VERSION ""

NS_ :

BS_:

BU_: BMS Third_Party_Device

BO_ 1712 MSGID_0X6B0: 8 BMS
 SG_ Pack_Current : 7|16@0- (0.1,0) [32769|32767] "Amps"  Third_Party_Device
 SG_ Pack_Summed_Voltage : 23|16@0+ (0.1,0) [0|65535] "Volts"  Third_Party_Device
 SG_ Pack_SOC : 39|8@0+ (0.5,0) [0|255] "Percent"  Third_Party_Device
 SG_ MultiPurpose_Input_2 : 40|1@1+ (1.0,0) [0|1] ""  Third_Party_Device
 SG_ MultiPurpose_Input_3 : 41|1@1+ (1.0,0) [0|1] ""  Third_Party_Device
 SG_ Blank : 42|1@1+ (1.0,0) [0|1] ""  Third_Party_Device
 SG_ MultiPurpose_Output_2 : 43|1@1+ (1.0,0) [0|1] ""  Third_Party_Device
 SG_ MultiPurpose_Output_3 : 44|1@1+ (1.0,0) [0|1] ""  Third_Party_Device
 SG_ MultiPurpose_Output_4 : 45|1@1+ (1.0,0) [0|1] ""  Third_Party_Device
 SG_ MultiPurpose_Enable : 46|1@1+ (1.0,0) [0|1] ""  Third_Party_Device
 SG_ MultiPurpose_Output : 47|1@1+ (1.0,0) [0|1] ""  Third_Party_Device
 SG_ Discharge_Relay : 48|1@1+ (1.0,0) [0|1] ""  Third_Party_Device
 SG_ Charge_Relay : 49|1@1+ (1.0,0) [0|1] ""  Third_Party_Device
 SG_ Charger_Safety : 50|1@1+ (1.0,0) [0|1] ""  Third_Party_Device
 SG_ Error_MIL_Output : 51|1@1+ (1.0,0) [0|1] ""  Third_Party_Device
 SG_ MultiPurpose_Input : 52|1@1+ (1.0,0) [0|1] ""  Third_Party_Device
 SG_ Constant_1 : 53|1@1+ (1.0,0) [0|1] ""  Third_Party_Device
 SG_ Ready_Power_Signal : 54|1@1+ (1.0,0) [0|1] ""  Third_Party_Device
 SG_ Charge_Power_Signal : 55|1@1+ (1.0,0) [0|1] ""  Third_Party_Device
 SG_ CRC_Checksum : 63|8@0+ (1.0,1) [0|0] ""  Third_Party_Device

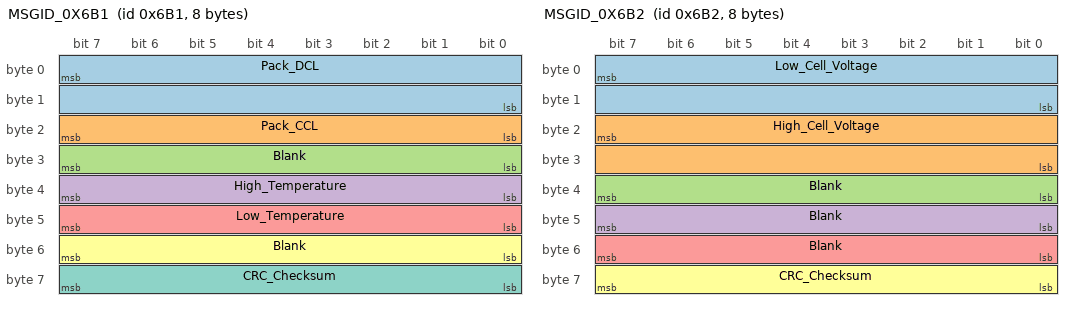
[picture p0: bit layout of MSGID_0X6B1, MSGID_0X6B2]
BO_ 1713 MSGID_0X6B1: 8 BMS
 SG_ Pack_DCL : 7|16@0+ (1.0,0) [0|65535] "Amps"  Third_Party_Device
 SG_ Pack_CCL : 23|8@0+ (1.0,0) [0|255] "Amps"  Third_Party_Device
 SG_ Blank : 31|8@0+ (1.0,0) [0|0] ""  Third_Party_Device
 SG_ High_Temperature : 39|8@0- (1.0,0) [65408|127] "Celsius"  Third_Party_Device
 SG_ Low_Temperature : 47|8@0- (1.0,0) [65408|127] "Celsius"  Third_Party_Device
 SG_ Blank : 55|8@0+ (1.0,0) [0|0] ""  Third_Party_Device
 SG_ CRC_Checksum : 63|8@0+ (1.0,1721) [0|0] ""  Third_Party_Device

BO_ 1714 MSGID_0X6B2: 8 BMS
 SG_ Low_Cell_Voltage : 7|16@0+ (1.0E-4,0) [0|65535] "Volts"  Third_Party_Device
 SG_ High_Cell_Voltage : 23|16@0+ (1.0E-4,0) [0|65535] "Volts"  Third_Party_Device
 SG_ Blank : 39|8@0+ (1.0,0) [0|0] ""  Third_Party_Device
 SG_ Blank : 47|8@0+ (1.0,0) [0|0] ""  Third_Party_Device
 SG_ Blank : 55|8@0+ (1.0,0) [0|0] ""  Third_Party_Device
 SG_ CRC_Checksum : 63|8@0+ (1.0,0) [0|0] ""  Third_Party_Device

BO_ 1281 MSGID_0X501: 2 Third_Party_Device
 SG_ MPO4_State : 7|8@0+ (1.0,0) [0|0] "ON/OFF"  BMS
 SG_ MPO3_State : 15|8@0+ (1.0,0) [0|0] "ON/OFF"  BMS

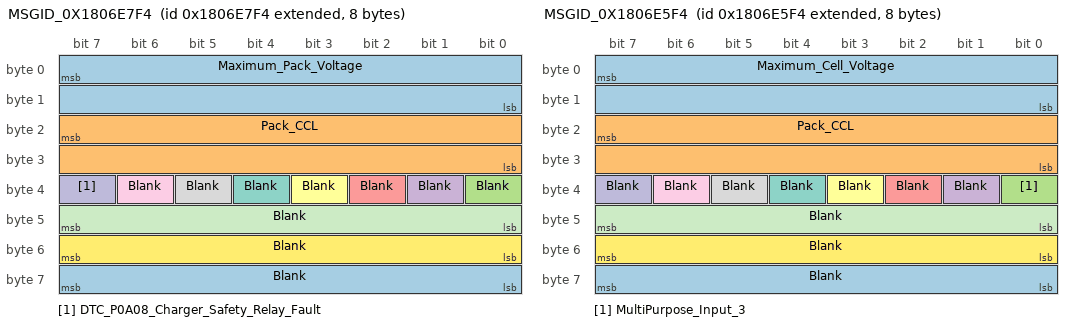
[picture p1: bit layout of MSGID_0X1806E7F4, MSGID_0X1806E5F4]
BO_ 2550589428 MSGID_0X1806E7F4: 8 BMS
 SG_ Maximum_Pack_Voltage : 7|16@0+ (0.1,0) [0|0] "Volts"  Third_Party_Device
 SG_ Pack_CCL : 23|16@0+ (0.1,0) [0|0] "Amps"  Third_Party_Device
 SG_ Blank : 32|1@1+ (1.0,0) [0|1] ""  Third_Party_Device
 SG_ Blank : 33|1@1+ (1.0,0) [0|1] ""  Third_Party_Device
 SG_ Blank : 34|1@1+ (1.0,0) [0|1] ""  Third_Party_Device
 SG_ Blank : 35|1@1+ (1.0,0) [0|1] ""  Third_Party_Device
 SG_ Blank : 36|1@1+ (1.0,0) [0|1] ""  Third_Party_Device
 SG_ Blank : 37|1@1+ (1.0,0) [0|1] ""  Third_Party_Device
 SG_ Blank : 38|1@1+ (1.0,0) [0|1] ""  Third_Party_Device
 SG_ DTC_P0A08_Charger_Safety_Relay_Fault : 39|1@1+ (1.0,0) [0|1] ""  Third_Party_Device
 SG_ Blank : 47|8@0+ (0.1,0) [0|0] ""  Third_Party_Device
 SG_ Blank : 55|8@0+ (1.0,0) [0|0] ""  Third_Party_Device
 SG_ Blank : 63|8@0+ (1.0,0) [0|0] ""  Third_Party_Device

BO_ 2550588916 MSGID_0X1806E5F4: 8 BMS
 SG_ Maximum_Cell_Voltage : 7|16@0+ (0.001,0) [0|0] "Volts"  Third_Party_Device
 SG_ Pack_CCL : 23|16@0+ (0.1,0) [0|0] "Amps"  Third_Party_Device
 SG_ MultiPurpose_Input_3 : 32|1@1+ (1.0,0) [0|1] ""  Third_Party_Device
 SG_ Blank : 33|1@1+ (1.0,0) [0|1] ""  Third_Party_Device
 SG_ Blank : 34|1@1+ (1.0,0) [0|1] ""  Third_Party_Device
 SG_ Blank : 35|1@1+ (1.0,0) [0|1] ""  Third_Party_Device
 SG_ Blank : 36|1@1+ (1.0,0) [0|1] ""  Third_Party_Device
 SG_ Blank : 37|1@1+ (1.0,0) [0|1] ""  Third_Party_Device
 SG_ Blank : 38|1@1+ (1.0,0) [0|1] ""  Third_Party_Device
 SG_ Blank : 39|1@1+ (1.0,0) [0|1] ""  Third_Party_Device
 SG_ Blank : 47|8@0+ (1.0,4) [0|0] ""  Third_Party_Device
 SG_ Blank : 55|8@0+ (1.0,0) [0|0] ""  Third_Party_Device
 SG_ Blank : 63|8@0+ (1.0,0) [0|0] ""  Third_Party_Device

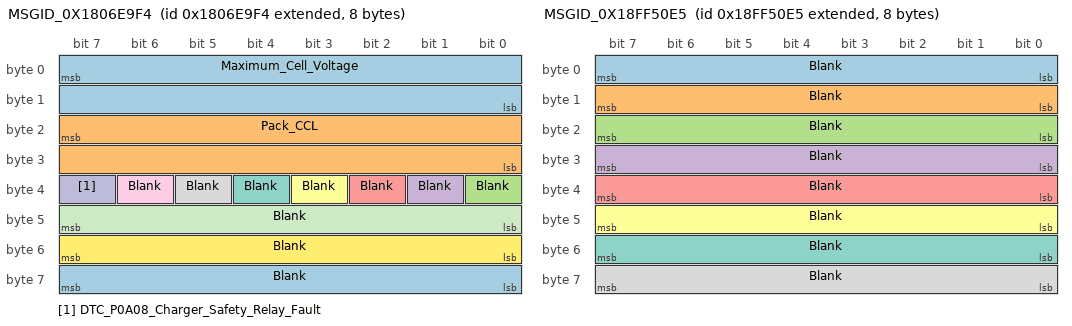
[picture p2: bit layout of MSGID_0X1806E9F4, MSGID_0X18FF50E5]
BO_ 2550589940 MSGID_0X1806E9F4: 8 BMS
 SG_ Maximum_Cell_Voltage : 7|16@0+ (0.001,0) [0|0] "Volts"  Third_Party_Device
 SG_ Pack_CCL : 23|16@0+ (0.1,0) [0|0] "Amps"  Third_Party_Device
 SG_ Blank : 32|1@1+ (1.0,0) [0|1] ""  Third_Party_Device
 SG_ Blank : 33|1@1+ (1.0,0) [0|1] ""  Third_Party_Device
 SG_ Blank : 34|1@1+ (1.0,0) [0|1] ""  Third_Party_Device
 SG_ Blank : 35|1@1+ (1.0,0) [0|1] ""  Third_Party_Device
 SG_ Blank : 36|1@1+ (1.0,0) [0|1] ""  Third_Party_Device
 SG_ Blank : 37|1@1+ (1.0,0) [0|1] ""  Third_Party_Device
 SG_ Blank : 38|1@1+ (1.0,0) [0|1] ""  Third_Party_Device
 SG_ DTC_P0A08_Charger_Safety_Relay_Fault : 39|1@1+ (1.0,0) [0|1] ""  Third_Party_Device
 SG_ Blank : 47|8@0+ (1.0,0) [0|0] ""  Third_Party_Device
 SG_ Blank : 55|8@0+ (1.0,0) [0|0] ""  Third_Party_Device
 SG_ Blank : 63|8@0+ (1.0,0) [0|0] ""  Third_Party_Device

BO_ 2566869221 MSGID_0X18FF50E5: 8 Third_Party_Device
 SG_ Blank : 7|8@0+ (1.0,0) [0|0] ""  BMS
 SG_ Blank : 15|8@0+ (1.0,0) [0|0] ""  BMS
 SG_ Blank : 23|8@0+ (1.0,0) [0|0] ""  BMS
 SG_ Blank : 31|8@0+ (1.0,0) [0|0] ""  BMS
 SG_ Blank : 39|8@0+ (1.0,0) [0|0] ""  BMS
 SG_ Blank : 47|8@0+ (1.0,0) [0|0] ""  BMS
 SG_ Blank : 55|8@0+ (1.0,0) [0|0] ""  BMS
 SG_ Blank : 63|8@0+ (1.0,0) [0|0] ""  BMS

CM_ BO_ 1712 "This ID Transmits at 8 ms.";
CM_ BO_ 1713 "This ID Transmits at 104 ms.";
CM_ BO_ 1714 "This ID Transmits at 8 ms.";
CM_ BO_ 2550589428 "This ID Transmits at 808 ms.";
CM_ BO_ 2550588916 "This ID Transmits at 808 ms.";
CM_ BO_ 2550589940 "This ID Transmits at 808 ms.";
